# MKM33ZA5 register map
Vendor: Freescale Semiconductor, Inc.; File version: 1.6
CPU: CM0PLUS r0p0, little endian, no MPU, no FPU, 0x2 interrupt priority bits, 0x0 interrupts
Registers are 32-bit, read-write, reset 0x0 unless marked. A register's access mark holds for its fields unless they carry their own. Offsets are from the block's base; [hi:lo] are bit positions; {n}, {i} and the like mark numbered series; 'fields as' and 'values as' point back to an identical list.

## ADC — Analog-to-Digital Converter
Base 0x4002B000; register names take the prefix ADC_
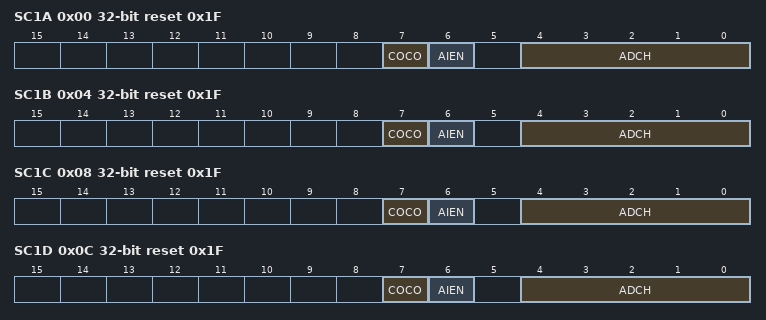
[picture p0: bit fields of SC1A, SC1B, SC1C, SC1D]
0x00 SC1A reset 0x1F — ADC Status and Control Registers 1
  [7] COCO ro — Conversion Complete Flag
    0=Conversion is not completed; 1=Conversion is completed
  [6] AIEN — Interrupt Enable
    0=Conversion complete interrupt is disabled; 1=Conversion complete interrupt is enabled
  [4:0] ADCH — Input channel select
    {v}=AD{v} is selected as input (v=0..23); 26=Temp Sensor (single-ended) is selected as input; 27=Bandgap (single-ended) is selected as input; 29=VREFSH is selected as input. Voltage reference selected is determined by SC2[REFSEL].; 30=VREFSL is selected as input. Voltage reference selected is determined by SC2[REFSEL].; 31=Module is disabled
0x04 SC1B reset 0x1F — ADC Status and Control Registers 1
  fields as SC1A
0x08 SC1C reset 0x1F — ADC Status and Control Registers 1
  fields as SC1A
0x0C SC1D reset 0x1F — ADC Status and Control Registers 1
  fields as SC1A
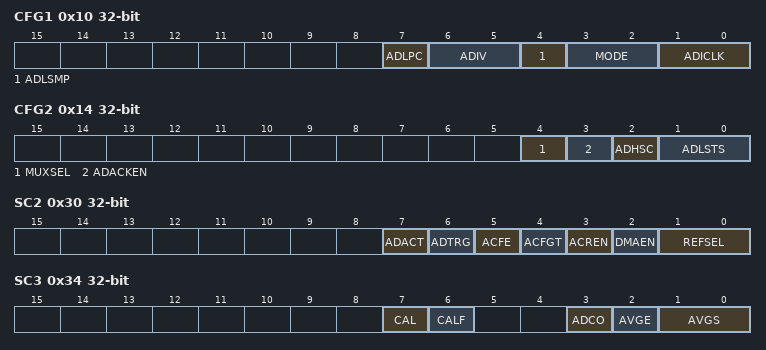
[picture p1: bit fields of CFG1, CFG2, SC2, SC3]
0x10 CFG1 — ADC Configuration Register 1
  [7] ADLPC — Low-Power Configuration
    0=Normal power configuration; 1=Low-power configuration. The power is reduced at the expense of maximum clock speed.
  [6:5] ADIV — Clock Divide Select
    0=The divide ratio is 1 and the clock rate is input clock; 1=The divide ratio is 2 and the clock rate is (input clock)/2; 2=The divide ratio is 4 and the clock rate is (input clock)/4; 3=The divide ratio is 8 and the clock rate is (input clock)/8
  [4] ADLSMP — Sample Time Configuration
    0=Short sample time; 1=Long sample time
  [3:2] MODE — Conversion mode selection
    0=It is single-ended 8-bit conversion; 1=It is single-ended 12-bit conversion ; 2=It is single-ended 10-bit conversion; 3=It is single-ended 16-bit conversion
  [1:0] ADICLK — Input Clock Select
    0=Bus clock; 1=Bus clock divided by 2(BUSCLK/DIV2); 2=Alternate clock (ALTCLK); 3=Asynchronous clock (ADACK)
0x14 CFG2 — ADC Configuration Register 2
  [4] MUXSEL — ADC Mux Select
    0=ADxxa channels are selected; 1=ADxxb channels are selected
  [3] ADACKEN — Asynchronous Clock Output Enable
    0=Asynchronous clock output disabled; Asynchronous clock is enabled only if selected by ADICLK and a conversion is active; 1=Asynchronous clock and clock output is enabled regardless of the state of the ADC
  [2] ADHSC — High-Speed Configuration
    0=Normal conversion sequence selected; 1=High-speed conversion sequence selected with 2 additional ADCK cycles to total conversion time
  [1:0] ADLSTS — Long Sample Time Select
    0=Default longest sample time; 20 extra ADCK cycles; 24 ADCK cycles total; 1=12 extra ADCK cycles; 16 ADCK cycles total sample time; 2=6 extra ADCK cycles; 10 ADCK cycles total sample time; 3=2 extra ADCK cycles; 6 ADCK cycles total sample time
0x18 RA ro — ADC Data Result Register
  [15:0] D — Data result
0x1C RB ro — ADC Data Result Register
  [15:0] D — Data result
0x20 RC ro — ADC Data Result Register
  [15:0] D — Data result
0x24 RD ro — ADC Data Result Register
  [15:0] D — Data result
0x28 CV1 — Compare Value Registers
  [15:0] CV — Compare Value.
0x2C CV2 — Compare Value Registers
  [15:0] CV — Compare Value.
0x30 SC2 — Status and Control Register 2
  [7] ADACT ro — Conversion Active
    0=Conversion not in progress; 1=Conversion in progress
  [6] ADTRG — Conversion Trigger Select
    0=Software trigger selected; 1=Hardware trigger selected
  [5] ACFE — Compare Function Enable
    0=Compare function disabled; 1=Compare function enabled
  [4] ACFGT — Compare Function Greater Than Enable
    0=Configures less than threshold, outside range not inclusive and inside range not inclusive; functionality based on the values placed in CV1 and CV2; 1=Configures greater than or equal to threshold, outside and inside ranges inclusive; functionality based on the values placed in CV1 and CV2
  [3] ACREN — Compare Function Range Enable
    0=Range function disabled. Only CV1 is compared.; 1=Range function enabled. Both CV1 and CV2 are compared.
  [2] DMAEN — DMA Enable
    0=DMA is disabled; 1=DMA is enabled and will assert the ADC DMA request during an ADC conversion complete event noted when any of the SC1n[COCO] flags is asserted
  [1:0] REFSEL — Voltage Reference Selection
    0=Default voltage reference pin pair, that is, external pins VREFH and VREFL; 1=Alternate reference pair, that is, VALTH and VALTL . This pair may be additional external pins or internal sources depending on the MCU configuration. See the chip configuration information for details specific to this MCU; 2=Internal bandgap reference and associated ground reference (V BGH and V BGL ). Consult the Chip Configuration information for details specific to this MCU.
0x34 SC3 — Status and Control Register 3
  [7] CAL — Calibration
  [6] CALF — Calibration Failed Flag
    0=Calibration completed normally; 1=Calibration failed. ADC accuracy specifications are not guaranteed.
  [3] ADCO — Continuous Conversion Enable
    0=One conversion or one set of conversions if the hardware average function is enabled, that is, AVGE=1, after initiating a conversion; 1=Continuous conversions or sets of conversions if the hardware average function is enabled, that is, AVGE=1, after initiating a conversion
  [2] AVGE — Hardware Average Enable
    0=Hardware average function disabled; 1=Hardware average function enabled
  [1:0] AVGS — Hardware Average Select
    0=4 samples averaged; 1=8 samples averaged; 2=16 samples averaged; 3=32 samples averaged
0x38 OFS reset 0x4 — ADC Offset Correction Register
  [15:0] OFS — Offset Error Correction Value
0x3C PG reset 0x8200 — ADC Plus-Side Gain Register
  [15:0] PG — Plus-Side Gain
0x44 CLPD reset 0xA — ADC Plus-Side General Calibration Value Register
  [5:0] CLPD — Calibration Value
0x48 CLPS reset 0x20 — ADC Plus-Side General Calibration Value Register
  [5:0] CLPS — Calibration Value
0x4C CLP4 reset 0x200 — ADC Plus-Side General Calibration Value Register
  [9:0] CLP4 — Calibration Value
0x50 CLP3 reset 0x100 — ADC Plus-Side General Calibration Value Register
  [8:0] CLP3 — Calibration Value
0x54 CLP2 reset 0x80 — ADC Plus-Side General Calibration Value Register
  [7:0] CLP2 — Calibration Value
0x58 CLP1 reset 0x40 — ADC Plus-Side General Calibration Value Register
  [6:0] CLP1 — Calibration Value
0x5C CLP0 reset 0x20 — ADC Plus-Side General Calibration Value Register
  [5:0] CLP0 — Calibration Value
